# MKL03Z4 register map
Vendor: Freescale Semiconductor, Inc.; Series: Kinetis_L; File version: 1.6
MKL03Z4 Freescale Microcontroller
CPU: CM0PLUS r0p0, little endian, no MPU, no FPU, VTOR, 2 interrupt priority bits
Registers are 32-bit, read-write, reset 0x0 unless marked. A register's access mark holds for its fields unless they carry their own. Offsets are from the block's base; lines under a group give offsets from that group; [hi:lo] are bit positions; {n}, {i} and the like mark numbered series; 'fields as' and 'values as' point back to an identical list; <NAME> marks a mode.

## Memory map
0x00000400 FTFA_FlashConfig size 0xE — Flash configuration field
0x40020000 FTFA size 0x14 — Flash Memory Interface
0x40038000 TPM0 size 0x88 — Timer/PWM Module
0x40039000 TPM1 size 0x88 — Timer/PWM Module
0x4003B000 ADC0 size 0x50 — Analog-to-Digital Converter
0x4003D000 RTC size 0x20 — Secure Real Time Clock
0x40040000 LPTMR0 size 0x10 — Low Power Timer
0x40041000 RFSYS size 0x10 — System register file
0x40047000 SIM size 0x1108 — System Integration Module
0x40049000 PORTA size 0xA4 — Pin Control and Interrupts
0x4004A000 PORTB size 0xA4 — Pin Control and Interrupts
0x40054000 LPUART0 size 0x14 — Universal Asynchronous Receiver/Transmitter
0x40064000 MCG size 0x19 — Multipurpose Clock Generator Lite
0x40065000 OSC size 0x1 — Oscillator
0x40066000 I2C0 size 0xD — Inter-Integrated Circuit
0x40073000 CMP0 size 0x6 — High-Speed Comparator (CMP), Voltage Reference (VREF) Digital-to-Analog Converter (DAC), and Analog Mux (ANMUX)
0x40074000 VREF size 0x2 — Voltage Reference
0x40076000 SPI0 size 0x7 — Serial Peripheral Interface
0x4007C000 LLWU size 0x7 — Low leakage wakeup unit
0x4007D000 PMC size 0x3 — Power Management Controller
0x4007E000 SMC size 0x4 — System Mode Controller
0x4007F000 RCM size 0xA — Reset Control Module
0x400FF000 GPIOA size 0x18 — General Purpose Input/Output
0x400FF040 GPIOB size 0x18 — General Purpose Input/Output
0xF0000000 MTB size 0x1000 — Micro Trace Buffer
0xF0001000 MTBDWT size 0x1000 — MTB data watchpoint and trace
0xF0002000 ROM size 0x1000 — System ROM
0xF0003000 MCM blocks up to offset 0x44 — Core Platform Miscellaneous Control Module
0xF8000000 FGPIOA size 0x18 — General Purpose Input/Output
0xF8000040 FGPIOB size 0x18 — General Purpose Input/Output

## Interrupts
5 FTFA
6 PMC
7 LLWU
8 I2C0
10 SPI0
12 LPUART0
15 ADC0
16 CMP0
17 TPM0
18 TPM1
20 RTC
21 RTC_Seconds (RTC)
28 LPTMR0
30 PORTA (PORTA, GPIOA)
31 PORTB (PORTB, GPIOB)

## FTFA_FlashConfig — Flash configuration field
Base 0x00000400; register names take the prefix NV_
0x00 BACKKEY3 8-bit ro reset 0xFF — Backdoor Comparison Key 3.
  [7:0] KEY — Backdoor Comparison Key.
0x01 BACKKEY2 8-bit ro reset 0xFF — Backdoor Comparison Key 2.
  [7:0] KEY — Backdoor Comparison Key.
0x02 BACKKEY1 8-bit ro reset 0xFF — Backdoor Comparison Key 1.
  [7:0] KEY — Backdoor Comparison Key.
0x03 BACKKEY0 8-bit ro reset 0xFF — Backdoor Comparison Key 0.
  [7:0] KEY — Backdoor Comparison Key.
0x04 BACKKEY7 8-bit ro reset 0xFF — Backdoor Comparison Key 7.
  [7:0] KEY — Backdoor Comparison Key.
0x05 BACKKEY6 8-bit ro reset 0xFF — Backdoor Comparison Key 6.
  [7:0] KEY — Backdoor Comparison Key.
0x06 BACKKEY5 8-bit ro reset 0xFF — Backdoor Comparison Key 5.
  [7:0] KEY — Backdoor Comparison Key.
0x07 BACKKEY4 8-bit ro reset 0xFF — Backdoor Comparison Key 4.
  [7:0] KEY — Backdoor Comparison Key.
0x08 FPROT3 8-bit ro reset 0xFF — Non-volatile P-Flash Protection 1 - Low Register
  [7:0] PROT — P-Flash Region Protect
0x09 FPROT2 8-bit ro reset 0xFF — Non-volatile P-Flash Protection 1 - High Register
  [7:0] PROT — P-Flash Region Protect
0x0A FPROT1 8-bit ro reset 0xFF — Non-volatile P-Flash Protection 0 - Low Register
  [7:0] PROT — P-Flash Region Protect
0x0B FPROT0 8-bit ro reset 0xFF — Non-volatile P-Flash Protection 0 - High Register
  [7:0] PROT — P-Flash Region Protect
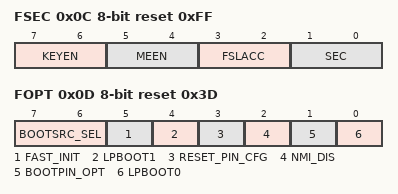
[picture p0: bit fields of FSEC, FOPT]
0x0C FSEC 8-bit ro reset 0xFF — Non-volatile Flash Security Register
  [7:6] KEYEN — Backdoor Key Security Enable
    2=Backdoor key access enabled; 3=Backdoor key access disabled
  [5:4] MEEN
    2=Mass erase is disabled; 3=Mass erase is enabled
  [3:2] FSLACC — Freescale Failure Analysis Access Code
    2=Freescale factory access denied; 3=Freescale factory access granted
  [1:0] SEC — Flash Security
    2=MCU security status is unsecure; 3=MCU security status is secure
0x0D FOPT 8-bit ro reset 0x3D — Non-volatile Flash Option Register
  [7:6] BOOTSRC_SEL — Boot source selection
    0=Boot from Flash; 2=Boot from ROM; 3=Boot from ROM
  [5] FAST_INIT
    0=Slower initialization; 1=Fast Initialization
  [4] LPBOOT1
    0=Core and system clock divider (OUTDIV1) is 0x7 (divide by 8) when LPBOOT0=0 or 0x3 (divide by 4) when LPBOOT0=1; 1=Core and system clock divider (OUTDIV1) is 0x1 (divide by 2) when LPBOOT0=0 or 0x0 (divide by 1) when LPBOOT0=1
  [3] RESET_PIN_CFG
    0=RESET pin is disabled following a POR and cannot be enabled as reset function; 1=RESET_b pin is dedicated
  [2] NMI_DIS
    0=NMI interrupts are always blocked; 1=NMI_b pin/interrupts reset default to enabled
  [1] BOOTPIN_OPT
    0=Force Boot from ROM if BOOTCFG0 asserted, where BOOTCFG0 is the boot config function which is muxed with NMI pin; 1=Boot source configured by FOPT (BOOTSRC_SEL) bits
  [0] LPBOOT0
    0=Core and system clock divider (OUTDIV1) is 0x7 (divide by 8) when LPBOOT1=0 or 0x1 (divide by 2) when LPBOOT1=1; 1=Core and system clock divider (OUTDIV1) is 0x3 (divide by 4) when LPBOOT1=0 or 0x0 (divide by 1) when LPBOOT1=1

## Licence text in the file
Redistribution and use in source and binary forms, with or without modification, are permitted provided that the following conditions are met: o Redistributions of source code must retain the above copyright notice, this list of conditions and the following disclaimer. o Redistributions in binary form must reproduce the above copyright notice, this list of conditions and the following disclaimer in the documentation and/or other materials provided with the distribution. o Neither the name of Freescale Semiconductor, Inc. nor the names of its contributors may be used to endorse or promote products derived from this software without specific prior written permission. THIS SOFTWARE IS PROVIDED BY THE COPYRIGHT HOLDERS AND CONTRIBUTORS "AS IS" AND. ANY EXPRESS OR IMPLIED WARRANTIES, INCLUDING, BUT NOT LIMITED TO, THE IMPLIED. WARRANTIES OF MERCHANTABILITY AND FITNESS FOR A PARTICULAR PURPOSE ARE. DISCLAIMED. IN NO EVENT SHALL THE COPYRIGHT HOLDER OR CONTRIBUTORS BE LIABLE FOR. ANY DIRECT, INDIRECT, INCIDENTAL, SPECIAL, EXEMPLARY, OR CONSEQUENTIAL DAMAGES (INCLUDING, BUT NOT LIMITED TO, PROCUREMENT OF SUBSTITUTE GOODS OR SERVICES; LOSS OF USE, DATA, OR PROFITS; OR BUSINESS INTERRUPTION) HOWEVER CAUSED AND ON. ANY THEORY OF LIABILITY, WHETHER IN CONTRACT, STRICT LIABILITY, OR TORT (INCLUDING NEGLIGENCE OR OTHERWISE) ARISING IN ANY WAY OUT OF THE USE OF THIS. SOFTWARE, EVEN IF ADVISED OF THE POSSIBILITY OF SUCH DAMAGE.
